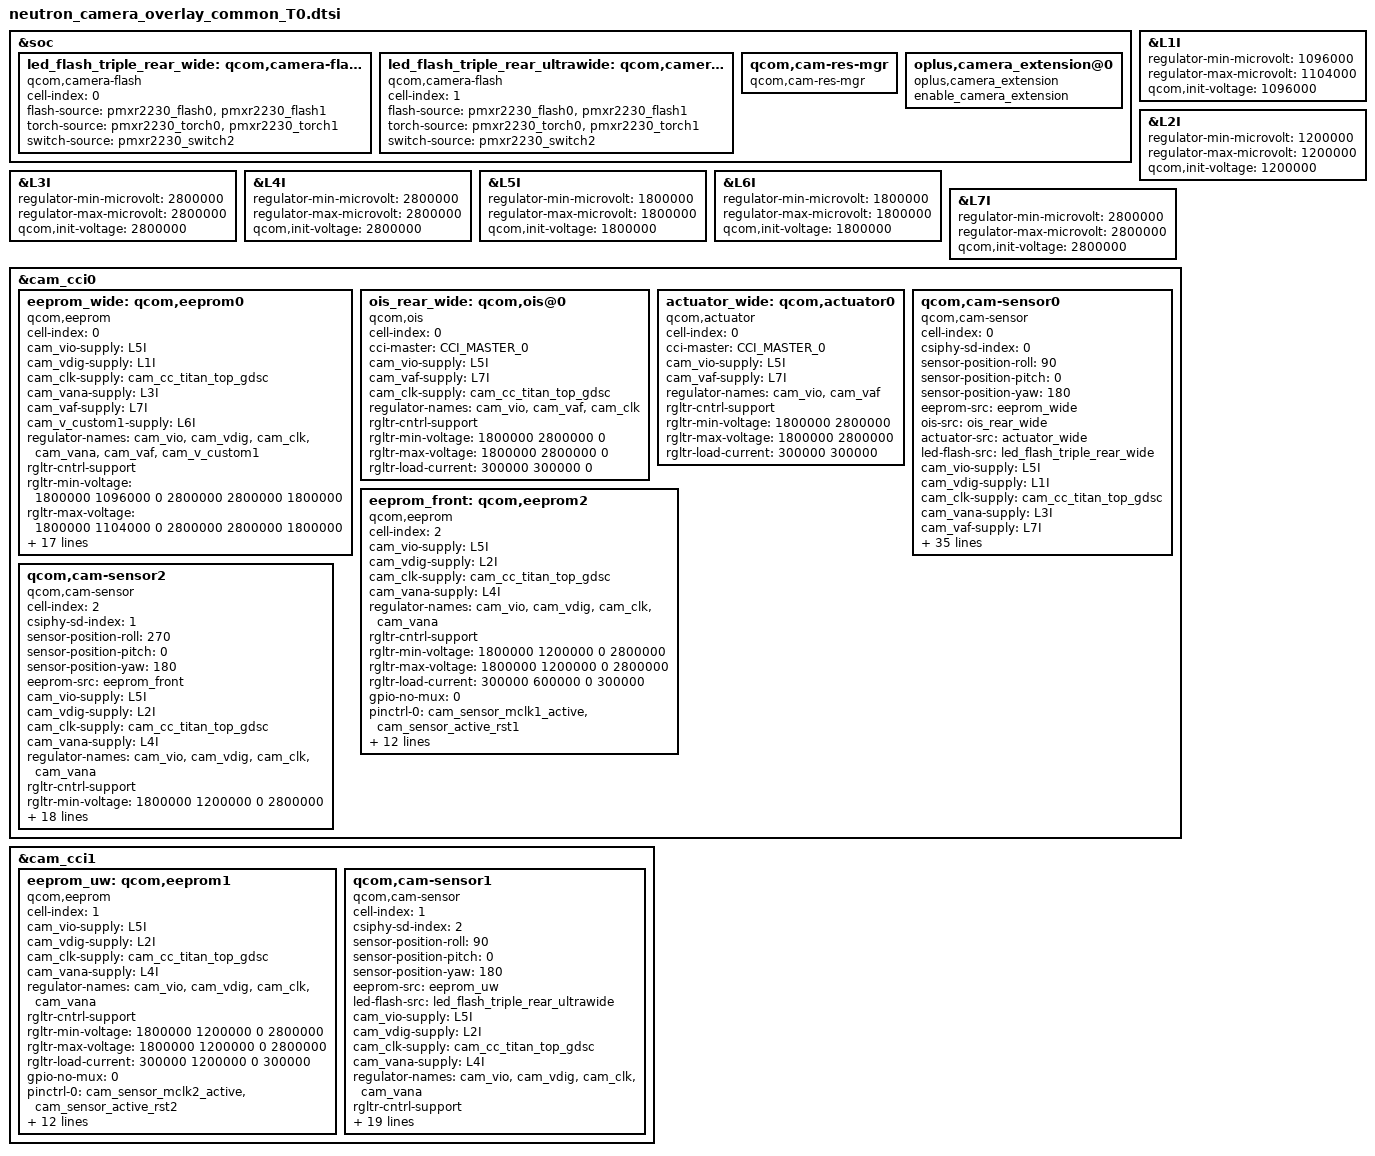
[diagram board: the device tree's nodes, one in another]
#include <dt-bindings/msm-camera.h>
#include "ftm_camera_settings.dtsi"

&soc {
        led_flash_triple_rear_wide: qcom,camera-flash0 {
                cell-index = <0>;
                compatible = "qcom,camera-flash";
                flash-source = <&pmxr2230_flash0 &pmxr2230_flash1>;
                torch-source = <&pmxr2230_torch0 &pmxr2230_torch1>;
                switch-source = <&pmxr2230_switch2>;
                status = "ok";
        };

        led_flash_triple_rear_ultrawide: qcom,camera-flash2 {
                cell-index = <1>;
                compatible = "qcom,camera-flash";
                flash-source = <&pmxr2230_flash0 &pmxr2230_flash1>;
                torch-source = <&pmxr2230_torch0 &pmxr2230_torch1>;
                switch-source = <&pmxr2230_switch2>;
                status = "ok";
        };


	qcom,cam-res-mgr {
		compatible = "qcom,cam-res-mgr";
		status = "ok";
	};

	oplus,camera_extension@0 {
		compatible = "oplus,camera_extension";
		enable_camera_extension;
		status = "ok";
	};
};

&L1I {
  regulator-min-microvolt = <1096000>;
  regulator-max-microvolt = <1104000>;
  qcom,init-voltage = <1096000>;
};

&L2I {
  regulator-min-microvolt = <1200000>;
  regulator-max-microvolt = <1200000>;
  qcom,init-voltage = <1200000>;
};

&L3I {
  regulator-min-microvolt = <2800000>;
  regulator-max-microvolt = <2800000>;
  qcom,init-voltage = <2800000>;
};

&L4I {
  regulator-min-microvolt = <2800000>;
  regulator-max-microvolt = <2800000>;
  qcom,init-voltage = <2800000>;
};

&L5I {
  regulator-min-microvolt = <1800000>;
  regulator-max-microvolt = <1800000>;
  qcom,init-voltage = <1800000>;
};

&L6I {
  regulator-min-microvolt = <1800000>;
  regulator-max-microvolt = <1800000>;
  qcom,init-voltage = <1800000>;
};


&L7I {
  regulator-min-microvolt = <2800000>;
  regulator-max-microvolt = <2800000>;
  qcom,init-voltage = <2800000>;
};

&cam_cci0 {
        eeprom_wide: qcom,eeprom0 {
                cell-index = <0>;
                compatible = "qcom,eeprom";
                cam_vio-supply = <&L5I>;
                cam_vdig-supply = <&L1I>;
                cam_clk-supply = <&cam_cc_titan_top_gdsc>;
                cam_vana-supply = <&L3I>;
                cam_vaf-supply = <&L7I>;
                cam_v_custom1-supply = <&L6I>;
                regulator-names = "cam_vio", "cam_vdig", "cam_clk", "cam_vana",
                        "cam_vaf", "cam_v_custom1";
                rgltr-cntrl-support;
                rgltr-min-voltage = <1800000 1096000 0 2800000 2800000 1800000>;
                rgltr-max-voltage = <1800000 1104000 0 2800000 2800000 1800000>;
                rgltr-load-current = <300000 1200000 0 300000 300000 300000>;
                gpio-no-mux = <0>;
                pinctrl-names = "cam_default", "cam_suspend";
                pinctrl-0 = <&cam_sensor_mclk0_active
                                &cam_sensor_active_rst0>;
                pinctrl-1 = <&cam_sensor_mclk0_suspend
                                &cam_sensor_suspend_rst0>;
                gpios = <&tlmm 65 0>,
                        <&tlmm 123 0>;
                gpio-reset = <1>;
                gpio-req-tbl-num = <0 1>;
                gpio-req-tbl-flags = <1 0>;
                gpio-req-tbl-label = "CAMIF_MCLK0",
                                        "CAM_RESET0";
                cci-master = <CCI_MASTER_0>;
                clocks = <&cambistmclkcc CAM_BIST_MCLK_CC_MCLK0_CLK>;
                clock-names = "cam_clk";
                clock-cntl-level = "nominal";
                clock-rates = <19200000>;
                status = "ok";
        };

        ois_rear_wide: qcom,ois@0{
                cell-index = <0>;
                compatible = "qcom,ois";
                cci-master = <CCI_MASTER_0>;
                cam_vio-supply = <&L5I>;
                cam_vaf-supply = <&L7I>;
                cam_clk-supply = <&cam_cc_titan_top_gdsc>;
                regulator-names = "cam_vio", "cam_vaf","cam_clk";
                rgltr-cntrl-support;
                rgltr-min-voltage = <1800000 2800000 0>;
                rgltr-max-voltage = <1800000 2800000 0>;
                rgltr-load-current = <300000 300000 0>;
                status = "ok";
        };

        actuator_wide: qcom,actuator0 {
                cell-index = <0>;
                compatible = "qcom,actuator";
                cci-master = <CCI_MASTER_0>;
                cam_vio-supply = <&L5I>;
                cam_vaf-supply = <&L7I>;
                regulator-names = "cam_vio", "cam_vaf";
                rgltr-cntrl-support;
                rgltr-min-voltage = <1800000 2800000>;
                rgltr-max-voltage = <1800000 2800000>;
                rgltr-load-current = <300000 300000>;
                status = "ok";
        };

	// wide camera
	qcom,cam-sensor0 {
		cell-index = <0>;
		compatible = "qcom,cam-sensor";
		csiphy-sd-index = <0>;
		sensor-position-roll = <90>;
		sensor-position-pitch = <0>;
		sensor-position-yaw = <180>;
		eeprom-src = <&eeprom_wide>;
		ois-src = <&ois_rear_wide>;
		actuator-src = <&actuator_wide>;
		led-flash-src = <&led_flash_triple_rear_wide>;
		cam_vio-supply = <&L5I>;
		cam_vdig-supply = <&L1I>;
		cam_clk-supply = <&cam_cc_titan_top_gdsc>;
		cam_vana-supply = <&L3I>;
		cam_vaf-supply = <&L7I>;
		cam_v_custom1-supply = <&L6I>;
		regulator-names = "cam_vio", "cam_vdig", "cam_clk", "cam_vana",
			"cam_vaf", "cam_v_custom1";
		rgltr-cntrl-support;
		rgltr-min-voltage = <1800000 1096000 0 2800000 2800000 1800000>;
		rgltr-max-voltage = <1800000 1104000 0 2800000 2800000 1800000>;
		rgltr-load-current = <300000 1200000 0 300000 300000 300000>;
		gpio-no-mux = <0>;
		pinctrl-names = "cam_default", "cam_suspend";
		pinctrl-0 = <&cam_sensor_mclk0_active
				&cam_sensor_active_rst0>;
		pinctrl-1 = <&cam_sensor_mclk0_suspend
				&cam_sensor_suspend_rst0>;
		gpios = <&tlmm 65 0>,
			<&tlmm 123 0>;
		gpio-reset = <1>;
		gpio-req-tbl-num = <0 1>;
		gpio-req-tbl-flags = <1 0>;
		gpio-req-tbl-label = "CAMIF_MCLK0",
					"CAM_RESET0";
		cci-master = <CCI_MASTER_0>;
		clocks = <&cambistmclkcc CAM_BIST_MCLK_CC_MCLK0_CLK>;
		clock-names = "cam_clk";
		clock-cntl-level = "nominal";
		clock-rates = <19200000>;
                is-support-laser = <1>;
		enable_qsc_write_in_advance = <1>;
		qsc_reg_addr = <0x22D0>;
		eeprom_slave_addr = <0xA0>;
		qsc_data_size = <3072>;
		write_qsc_addr = <0xC000>;
                //sensor_setting_id = <13>;
                ftm_setting_compatible = <'R' 0x0016 2 2 0x0896>; // expect camera_0016_090
		status = "ok";
		vsync_enable_reg_addr = <0x3051>;
		vsync_enable = <1>;
		vsync_disable = <0>;
	};

        eeprom_front: qcom,eeprom2 {
                cell-index = <2>;
                compatible = "qcom,eeprom";
                cam_vio-supply = <&L5I>;
                cam_vdig-supply = <&L2I>;
                cam_clk-supply = <&cam_cc_titan_top_gdsc>;
                cam_vana-supply = <&L4I>;
                regulator-names = "cam_vio", "cam_vdig","cam_clk", "cam_vana";
                rgltr-cntrl-support;
                rgltr-min-voltage = <1800000 1200000 0 2800000>;
                rgltr-max-voltage = <1800000 1200000 0 2800000>;
                rgltr-load-current = <300000 600000 0  300000>;
                gpio-no-mux = <0>;
                pinctrl-names = "cam_default", "cam_suspend";
                pinctrl-0 = <&cam_sensor_mclk1_active
                                 &cam_sensor_active_rst1>;
                pinctrl-1 = <&cam_sensor_mclk1_suspend
                                 &cam_sensor_suspend_rst1>;
                gpios = <&tlmm 66 0>,
                        <&tlmm 124 0>;
                gpio-reset = <1>;
                gpio-req-tbl-num = <0 1>;
                gpio-req-tbl-flags = <1 0>;
                gpio-req-tbl-label = "CAMIF_MCLK1",
                                        "CAM_RESET1";
                cci-master = <CCI_MASTER_1>;
                clocks = <&cambistmclkcc CAM_BIST_MCLK_CC_MCLK1_CLK>;
                clock-names = "cam_clk";
                clock-cntl-level = "nominal";
                clock-rates = <19200000>;
                status = "ok";
        };

        // front camera
        qcom,cam-sensor2 {
                cell-index = <2>;
                compatible = "qcom,cam-sensor";
                csiphy-sd-index = <1>;
                sensor-position-roll = <270>;
                sensor-position-pitch = <0>;
                sensor-position-yaw = <180>;
                eeprom-src = <&eeprom_front>;
                cam_vio-supply = <&L5I>;
                cam_vdig-supply = <&L2I>;
                cam_clk-supply = <&cam_cc_titan_top_gdsc>;
                //cam_vaf-supply = <&L7I>;
                cam_vana-supply = <&L4I>;
                regulator-names = "cam_vio", "cam_vdig","cam_clk", "cam_vana";
                rgltr-cntrl-support;
                rgltr-min-voltage = <1800000 1200000 0 2800000>;
                rgltr-max-voltage = <1800000 1200000 0 2800000>;
                rgltr-load-current = <300000 600000 0 300000>;
                gpio-no-mux = <0>;
                pinctrl-names = "cam_default", "cam_suspend";
                pinctrl-0 = <&cam_sensor_mclk1_active
                                 &cam_sensor_active_rst1>;
                pinctrl-1 = <&cam_sensor_mclk1_suspend
                                 &cam_sensor_suspend_rst1>;
                gpios = <&tlmm 66 0>,
                        <&tlmm 124 0>;
                gpio-reset = <1>;
                gpio-req-tbl-num = <0 1>;
                gpio-req-tbl-flags = <1 0>;
                gpio-req-tbl-label = "CAMIF_MCLK1",
                                        "CAM_RESET1";
                cci-master = <CCI_MASTER_1>;
                clocks = <&cambistmclkcc CAM_BIST_MCLK_CC_MCLK1_CLK>;
                clock-names = "cam_clk";
                clock-cntl-level = "nominal";
                clock-rates = <19200000>;
                ftm_setting_compatible = <'R' 0x03F0 2 2 0x32E2>;
                status = "ok";
        };
};

&cam_cci1 {

        eeprom_uw: qcom,eeprom1 {
                cell-index = <1>;
                compatible = "qcom,eeprom";
                cam_vio-supply = <&L5I>;
                cam_vdig-supply = <&L2I>;
                cam_clk-supply = <&cam_cc_titan_top_gdsc>;
                cam_vana-supply = <&L4I>;
                regulator-names = "cam_vio", "cam_vdig","cam_clk", "cam_vana";
                rgltr-cntrl-support;
                rgltr-min-voltage = <1800000 1200000 0 2800000>;
                rgltr-max-voltage = <1800000 1200000 0 2800000>;
                rgltr-load-current = <300000 1200000 0 300000 >;
                gpio-no-mux = <0>;
                pinctrl-names = "cam_default", "cam_suspend";
                pinctrl-0 = <&cam_sensor_mclk2_active
                                &cam_sensor_active_rst2>;
                pinctrl-1 = <&cam_sensor_mclk2_suspend
                                &cam_sensor_suspend_rst2>;
                gpios = <&tlmm 67 0>,
                        <&tlmm 125 0>;
                gpio-reset = <1>;
                gpio-req-tbl-num = <0 1>;
                gpio-req-tbl-flags = <1 0>;
                gpio-req-tbl-label = "CAMIF_MCLK2",
                                        "CAM_RESET2";
                cci-master = <CCI_MASTER_0>;
                clocks = <&cambistmclkcc CAM_BIST_MCLK_CC_MCLK2_CLK>;
                clock-names = "cam_clk";
                clock-cntl-level = "nominal";
                clock-rates = <19200000>;
                status = "ok";
        };

        // ultrawide camera
        qcom,cam-sensor1 {
                cell-index = <1>;
                compatible = "qcom,cam-sensor";
                csiphy-sd-index = <2>;
                sensor-position-roll = <90>;
                sensor-position-pitch = <0>;
                sensor-position-yaw = <180>;
                eeprom-src = <&eeprom_uw>;
		led-flash-src = <&led_flash_triple_rear_ultrawide>;
                cam_vio-supply = <&L5I>;
                cam_vdig-supply = <&L2I>;
                cam_clk-supply = <&cam_cc_titan_top_gdsc>;
                cam_vana-supply = <&L4I>;
                regulator-names = "cam_vio", "cam_vdig","cam_clk", "cam_vana";
                rgltr-cntrl-support;
                rgltr-min-voltage = <1800000 1200000 0 2800000>;
                rgltr-max-voltage = <1800000 1200000 0 2800000>;
                rgltr-load-current = <300000 1200000 0 300000 >;
                gpio-no-mux = <0>;
                pinctrl-names = "cam_default", "cam_suspend";
                pinctrl-0 = <&cam_sensor_mclk2_active
                                &cam_sensor_active_rst2>;
                pinctrl-1 = <&cam_sensor_mclk2_suspend
                                &cam_sensor_suspend_rst2>;
                gpios = <&tlmm 67 0>,
                        <&tlmm 125 0>;
                gpio-reset = <1>;
                gpio-req-tbl-num = <0 1>;
                gpio-req-tbl-flags = <1 0>;
                gpio-req-tbl-label = "CAMIF_MCLK2",
                                        "CAM_RESET2";
                cci-master = <CCI_MASTER_0>;
                clocks = <&cambistmclkcc CAM_BIST_MCLK_CC_MCLK2_CLK>;
                clock-names = "cam_clk";
                clock-cntl-level = "nominal";
                clock-rates = <19200000>;
                ftm_setting_compatible = <'R' 0x0000 1 2 0x5608>;
                status = "ok";
        };

};
